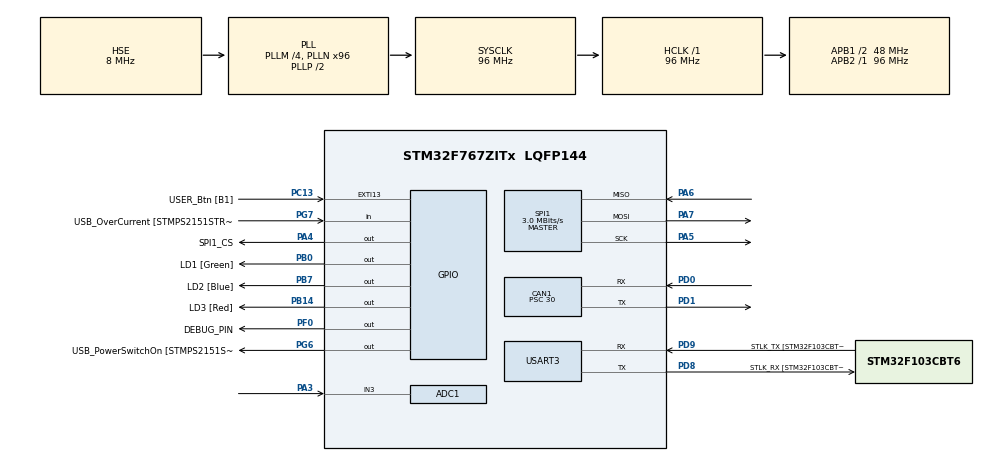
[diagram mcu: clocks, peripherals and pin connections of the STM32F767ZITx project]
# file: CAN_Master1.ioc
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ADC1.Channel-2\#ChannelRegularConversion=ADC_CHANNEL_3
ADC1.NbrOfConversion=1
ADC1.NbrOfConversionFlag=1
ADC1.Rank-2\#ChannelRegularConversion=1
ADC1.SamplingTime-2\#ChannelRegularConversion=ADC_SAMPLETIME_3CYCLES
ADC1.master=1
CAN1.BS1=CAN_BS1_13TQ
CAN1.BS2=CAN_BS2_2TQ
CAN1.CalculateBaudRate=100000
CAN1.CalculateTimeBit=10000
CAN1.CalculateTimeQuantum=625.0
CAN1.Prescaler=30
Mcu.Family=STM32F7
Mcu.Name=STM32F767ZITx
Mcu.Package=LQFP144
NVIC.PriorityGroup=NVIC_PRIORITYGROUP_4
NVIC.TIM6_DAC_IRQn=true\:0\:0\:true\:false\:true\:true\:true\:true
NVIC.USART3_IRQn=true\:1\:0\:true\:false\:true\:true\:true\:true
PA13.GPIO_Label=TMS
PA13.Mode=Serial_Wire
PA13.Signal=SYS_JTMS-SWDIO
PA14.GPIO_Label=TCK
PA14.Mode=Serial_Wire
PA14.Signal=SYS_JTCK-SWCLK
PA3.Signal=ADCx_IN3
PA4.GPIO_Label=SPI1_CS
PA4.GPIO_Speed=GPIO_SPEED_FREQ_VERY_HIGH
PA4.PinState=GPIO_PIN_RESET
PA4.Signal=GPIO_Output
PA5.Mode=Full_Duplex_Master
PA5.Signal=SPI1_SCK
PA6.Mode=Full_Duplex_Master
PA6.Signal=SPI1_MISO
PA7.Mode=Full_Duplex_Master
PA7.Signal=SPI1_MOSI
PB0.GPIO_Label=LD1 [Green]
PB0.Signal=GPIO_Output
PB14.GPIO_Label=LD3 [Red]
PB14.Signal=GPIO_Output
PB3.GPIO_Label=SWO
PB3.Signal=SYS_JTDO-SWO
PB7.GPIO_Label=LD2 [Blue]
PB7.Signal=GPIO_Output
PC13.GPIO_Label=USER_Btn [B1]
PC13.Signal=GPXTI13
PC14/OSC32_IN.Mode=LSE-External-Oscillator
PC14/OSC32_IN.Signal=RCC_OSC32_IN
PC15/OSC32_OUT.Mode=LSE-External-Oscillator
PC15/OSC32_OUT.Signal=RCC_OSC32_OUT
PD0.GPIO_PuPd=GPIO_PULLUP
PD0.Mode=CAN_Activate
PD0.Signal=CAN1_RX
PD1.GPIO_PuPd=GPIO_PULLUP
PD1.Mode=CAN_Activate
PD1.Signal=CAN1_TX
PD8.GPIO_Label=STLK_RX [STM32F103CBT6_PA3]
PD8.Mode=Asynchronous
PD8.Signal=USART3_TX
PD9.GPIO_Label=STLK_TX [STM32F103CBT6_PA2]
PD9.Mode=Asynchronous
PD9.Signal=USART3_RX
PF0.GPIO_Label=DEBUG_PIN
PF0.Signal=GPIO_Output
PG6.GPIO_Label=USB_PowerSwitchOn [STMPS2151STR_EN]
PG6.Signal=GPIO_Output
PG7.GPIO_Label=USB_OverCurrent [STMPS2151STR_FAULT]
PG7.Signal=GPIO_Input
PH0/OSC_IN.GPIO_Label=MCO [STM32F103CBT6_PA8]
PH0/OSC_IN.Mode=HSE-External-Clock-Source
PH0/OSC_IN.Signal=RCC_OSC_IN
PH1/OSC_OUT.Mode=HSE-External-Clock-Source
PH1/OSC_OUT.Signal=RCC_OSC_OUT
ProjectManager.HeapSize=0x200
ProjectManager.StackSize=0x400
ProjectManager.TargetToolchain=STM32CubeIDE
RCC.48MHZClocksFreq_Value=24000000
RCC.AHBFreq_Value=96000000
RCC.APB1CLKDivider=RCC_HCLK_DIV2
RCC.APB1Freq_Value=48000000
RCC.APB1TimFreq_Value=96000000
RCC.APB2Freq_Value=96000000
RCC.APB2TimFreq_Value=96000000
RCC.CortexFreq_Value=96000000
RCC.HCLKFreq_Value=96000000
RCC.HSE_VALUE=8000000
RCC.HSI_VALUE=16000000
RCC.PLLM=4
RCC.PLLMUL=RCC_PLL_MUL9
RCC.PLLN=96
RCC.PLLQ=4
RCC.PLLSourceVirtual=RCC_PLLSOURCE_HSE
RCC.PRESCALERUSB=RCC_USBCLKSOURCE_PLL_DIV1_5
RCC.SYSCLKFreq_VALUE=96000000
RCC.SYSCLKSource=RCC_SYSCLKSOURCE_PLLCLK
RCC.SYSCLKSourceVirtual=RCC_SYSCLKSOURCE_PLLCLK
RCC.USBFreq_Value=48000000
RCC.VCOOutputFreq_Value=192000000
SH.ADCx_IN3.0=ADC1_IN3,IN3
SPI1.BaudRatePrescaler=SPI_BAUDRATEPRESCALER_32
SPI1.CalculateBaudRate=3.0 MBits/s
SPI1.DataSize=SPI_DATASIZE_8BIT
SPI1.Direction=SPI_DIRECTION_2LINES
SPI1.Mode=SPI_MODE_MASTER
SPI1.VirtualType=VM_MASTER
TIM6.AutoReloadPreload=TIM_AUTORELOAD_PRELOAD_ENABLE
TIM6.Period=999
TIM6.Prescaler=9599
USART3.VirtualMode-Asynchronous=VM_ASYNC
VP_TIM6_VS_ClockSourceINT.Mode=Enable_Timer
board=NUCLEO-F767ZI

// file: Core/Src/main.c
/* USER CODE BEGIN Header */
/**
  ******************************************************************************
  * @file           : main.c
  * @brief          : Main program body
  ******************************************************************************
  * @attention
  *
  * Copyright (c) 2023 STMicroelectronics.
  * All rights reserved.
  *
  * This software is licensed under terms that can be found in the LICENSE file
  * in the root directory of this software component.
  * If no LICENSE file comes with this software, it is provided AS-IS.
  *
  ******************************************************************************
  */
/* USER CODE END Header */
#include "main.h"
#include "adc.h"
#include "can.h"
#include "spi.h"
#include "tim.h"
#include "usart.h"
#include "gpio.h"

/* USER CODE BEGIN Includes */

#include "app_can.h"
#include "app_uart.h"
#include "app_imu.h"
#include "app_system.h"
/* USER CODE END Includes */

void SystemClock_Config(void);

int main(void)
{

  /* MCU Configuration--------------------------------------------------------*/

  /* Reset of all peripherals, Initializes the Flash interface and the Systick. */
  HAL_Init();

  /* Configure the system clock */
  SystemClock_Config();

  /* Initialize all configured peripherals */
  MX_GPIO_Init();
  MX_USART3_UART_Init();
  MX_CAN1_Init();
  MX_TIM6_Init();
  MX_SPI1_Init();
  MX_ADC1_Init();
  /* USER CODE BEGIN 2 */

  AppImu_Init();
  AppCan_Init();
  AppSystem_Init();
  AppUart_Init();

  /* USER CODE END 2 */

  /* Infinite loop */
  while (1)
  {

  }
}

void SystemClock_Config(void)
{
  RCC_OscInitTypeDef RCC_OscInitStruct = {0};
  RCC_ClkInitTypeDef RCC_ClkInitStruct = {0};

  /** Configure LSE Drive Capability
  */
  HAL_PWR_EnableBkUpAccess();

  /** Configure the main internal regulator output voltage
  */
  __HAL_RCC_PWR_CLK_ENABLE();
  __HAL_PWR_VOLTAGESCALING_CONFIG(PWR_REGULATOR_VOLTAGE_SCALE3);

  /** Initializes the RCC Oscillators according to the specified parameters
  * in the RCC_OscInitTypeDef structure.
  */
  RCC_OscInitStruct.OscillatorType = RCC_OSCILLATORTYPE_HSE;
  RCC_OscInitStruct.HSEState = RCC_HSE_BYPASS;
  RCC_OscInitStruct.PLL.PLLState = RCC_PLL_ON;
  RCC_OscInitStruct.PLL.PLLSource = RCC_PLLSOURCE_HSE;
  RCC_OscInitStruct.PLL.PLLM = 4;
  RCC_OscInitStruct.PLL.PLLN = 96;
  RCC_OscInitStruct.PLL.PLLP = RCC_PLLP_DIV2;
  RCC_OscInitStruct.PLL.PLLQ = 4;
  RCC_OscInitStruct.PLL.PLLR = 2;
  if (HAL_RCC_OscConfig(&RCC_OscInitStruct) != HAL_OK)
  {
    Error_Handler();
  }

  /** Activate the Over-Drive mode
  */
  if (HAL_PWREx_EnableOverDrive() != HAL_OK)
  {
    Error_Handler();
  }

  /** Initializes the CPU, AHB and APB buses clocks
  */
  RCC_ClkInitStruct.ClockType = RCC_CLOCKTYPE_HCLK|RCC_CLOCKTYPE_SYSCLK
                              |RCC_CLOCKTYPE_PCLK1|RCC_CLOCKTYPE_PCLK2;
  RCC_ClkInitStruct.SYSCLKSource = RCC_SYSCLKSOURCE_PLLCLK;
  RCC_ClkInitStruct.AHBCLKDivider = RCC_SYSCLK_DIV1;
  RCC_ClkInitStruct.APB1CLKDivider = RCC_HCLK_DIV2;
  RCC_ClkInitStruct.APB2CLKDivider = RCC_HCLK_DIV1;

  if (HAL_RCC_ClockConfig(&RCC_ClkInitStruct, FLASH_LATENCY_3) != HAL_OK)
  {
    Error_Handler();
  }
}

/* USER CODE BEGIN 4 */

void HAL_TIM_PeriodElapsedCallback(TIM_HandleTypeDef *htim)
{
	if(htim->Instance == TIM6)
	{
		AppSystem_MainTask();
	}
}

void HAL_UART_RxCpltCallback(UART_HandleTypeDef *huart)
{
	if(huart->Instance == USART3)
	{
		AppUart_ProcessInput();
	}
}

/* USER CODE END 4 */

void Error_Handler(void)
{
  __disable_irq();
  while (1)
  {
  }
}
